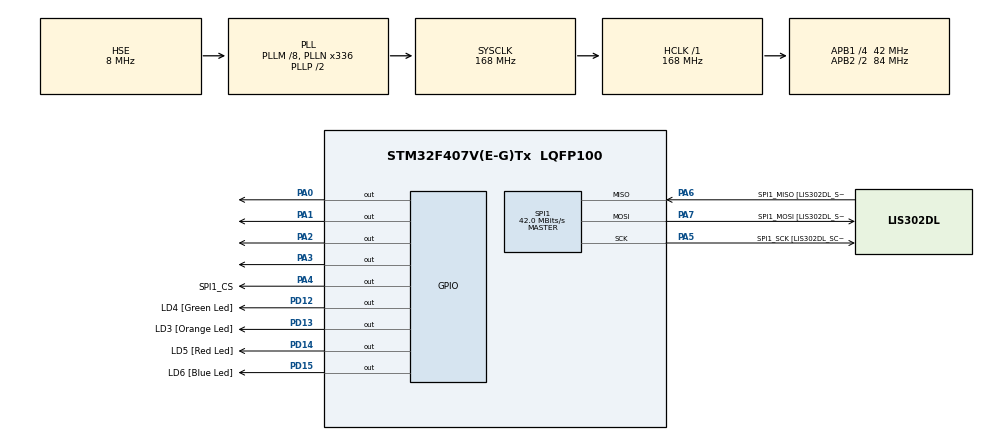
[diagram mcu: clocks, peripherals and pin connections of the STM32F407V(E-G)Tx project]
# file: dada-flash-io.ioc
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Dma.Request0=SPI1_RX
Dma.Request1=SPI1_TX
Dma.SPI1_RX.0.Direction=DMA_PERIPH_TO_MEMORY
Dma.SPI1_RX.0.FIFOMode=DMA_FIFOMODE_DISABLE
Dma.SPI1_RX.0.Instance=DMA2_Stream0
Dma.SPI1_RX.0.MemDataAlignment=DMA_MDATAALIGN_BYTE
Dma.SPI1_RX.0.MemInc=DMA_MINC_ENABLE
Dma.SPI1_RX.0.Mode=DMA_NORMAL
Dma.SPI1_RX.0.PeriphDataAlignment=DMA_PDATAALIGN_BYTE
Dma.SPI1_RX.0.PeriphInc=DMA_PINC_DISABLE
Dma.SPI1_RX.0.Priority=DMA_PRIORITY_LOW
Dma.SPI1_TX.1.Direction=DMA_MEMORY_TO_PERIPH
Dma.SPI1_TX.1.FIFOMode=DMA_FIFOMODE_DISABLE
Dma.SPI1_TX.1.Instance=DMA2_Stream3
Dma.SPI1_TX.1.MemDataAlignment=DMA_MDATAALIGN_BYTE
Dma.SPI1_TX.1.MemInc=DMA_MINC_ENABLE
Dma.SPI1_TX.1.Mode=DMA_NORMAL
Dma.SPI1_TX.1.PeriphDataAlignment=DMA_PDATAALIGN_BYTE
Dma.SPI1_TX.1.PeriphInc=DMA_PINC_DISABLE
Dma.SPI1_TX.1.Priority=DMA_PRIORITY_LOW
Mcu.Family=STM32F4
Mcu.Name=STM32F407V(E-G)Tx
Mcu.Package=LQFP100
NVIC.DMA2_Stream0_IRQn=true\:0\:0\:false\:false\:true\:false\:true
NVIC.DMA2_Stream3_IRQn=true\:0\:0\:false\:false\:true\:false\:true
NVIC.PriorityGroup=NVIC_PRIORITYGROUP_0
NVIC.SPI1_IRQn=true\:0\:0\:false\:false\:true\:true\:true
PA0-WKUP.Signal=GPIO_Output
PA1.Signal=GPIO_Output
PA2.Signal=GPIO_Output
PA3.Signal=GPIO_Output
PA4.GPIO_Label=SPI1_CS
PA4.GPIO_Speed=GPIO_SPEED_FREQ_MEDIUM
PA4.PinState=GPIO_PIN_SET
PA4.Signal=GPIO_Output
PA5.GPIO_Label=SPI1_SCK [LIS302DL_SCL/SPC]
PA5.GPIO_Mode=GPIO_MODE_AF_PP
PA5.GPIO_PuPd=GPIO_NOPULL
PA5.GPIO_Speed=GPIO_SPEED_FREQ_HIGH
PA5.Mode=Full_Duplex_Master
PA5.Signal=SPI1_SCK
PA6.GPIO_Label=SPI1_MISO [LIS302DL_SDO]
PA6.GPIO_Mode=GPIO_MODE_AF_PP
PA6.GPIO_PuPd=GPIO_NOPULL
PA6.GPIO_Speed=GPIO_SPEED_FREQ_HIGH
PA6.Mode=Full_Duplex_Master
PA6.Signal=SPI1_MISO
PA7.GPIO_Label=SPI1_MOSI [LIS302DL_SDA/SDI/SDO]
PA7.GPIO_Mode=GPIO_MODE_AF_PP
PA7.GPIO_PuPd=GPIO_NOPULL
PA7.GPIO_Speed=GPIO_SPEED_FREQ_HIGH
PA7.Mode=Full_Duplex_Master
PA7.Signal=SPI1_MOSI
PC14-OSC32_IN.GPIO_Label=PC14-OSC32_IN
PC14-OSC32_IN.Mode=LSE-External-Oscillator
PC14-OSC32_IN.Signal=RCC_OSC32_IN
PC15-OSC32_OUT.GPIO_Label=PC15-OSC32_OUT
PC15-OSC32_OUT.Mode=LSE-External-Oscillator
PC15-OSC32_OUT.Signal=RCC_OSC32_OUT
PD12.GPIO_Label=LD4 [Green Led]
PD12.GPIO_PuPd=GPIO_NOPULL
PD12.GPIO_Speed=GPIO_SPEED_FREQ_LOW
PD12.Signal=GPIO_Output
PD13.GPIO_Label=LD3 [Orange Led]
PD13.GPIO_PuPd=GPIO_NOPULL
PD13.GPIO_Speed=GPIO_SPEED_FREQ_LOW
PD13.Signal=GPIO_Output
PD14.GPIO_Label=LD5 [Red Led]
PD14.GPIO_PuPd=GPIO_NOPULL
PD14.GPIO_Speed=GPIO_SPEED_FREQ_LOW
PD14.Signal=GPIO_Output
PD15.GPIO_Label=LD6 [Blue Led]
PD15.GPIO_PuPd=GPIO_NOPULL
PD15.GPIO_Speed=GPIO_SPEED_FREQ_LOW
PD15.Signal=GPIO_Output
PH0-OSC_IN.GPIO_Label=PH0-OSC_IN
PH0-OSC_IN.Mode=HSE-External-Oscillator
PH0-OSC_IN.Signal=RCC_OSC_IN
PH1-OSC_OUT.GPIO_Label=PH1-OSC_OUT
PH1-OSC_OUT.Mode=HSE-External-Oscillator
PH1-OSC_OUT.Signal=RCC_OSC_OUT
ProjectManager.HeapSize=0x200
ProjectManager.StackSize=0x400
ProjectManager.TargetToolchain=STM32CubeIDE
RCC.48MHZClocksFreq_Value=48000000
RCC.AHBFreq_Value=168000000
RCC.APB1CLKDivider=RCC_HCLK_DIV4
RCC.APB1Freq_Value=42000000
RCC.APB1TimFreq_Value=84000000
RCC.APB2CLKDivider=RCC_HCLK_DIV2
RCC.APB2Freq_Value=84000000
RCC.APB2TimFreq_Value=168000000
RCC.CortexFreq_Value=168000000
RCC.HCLKFreq_Value=168000000
RCC.HSE_VALUE=8000000
RCC.HSI_VALUE=16000000
RCC.PLLM=8
RCC.PLLN=336
RCC.PLLQ=7
RCC.PLLSourceVirtual=RCC_PLLSOURCE_HSE
RCC.SYSCLKFreq_VALUE=168000000
RCC.SYSCLKSource=RCC_SYSCLKSOURCE_PLLCLK
RCC.VCOOutputFreq_Value=336000000
SPI1.BaudRatePrescaler=SPI_BAUDRATEPRESCALER_2
SPI1.CLKPhase=SPI_PHASE_1EDGE
SPI1.CLKPolarity=SPI_POLARITY_LOW
SPI1.CalculateBaudRate=42.0 MBits/s
SPI1.DataSize=SPI_DATASIZE_8BIT
SPI1.Direction=SPI_DIRECTION_2LINES
SPI1.FirstBit=SPI_FIRSTBIT_MSB
SPI1.Mode=SPI_MODE_MASTER
SPI1.VirtualType=VM_MASTER
board=STM32F407G-DISC1

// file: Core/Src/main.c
/* USER CODE BEGIN Header */
/**
  ******************************************************************************
  * @file           : main.c
  * @brief          : Main program body
  ******************************************************************************
  * @attention
  *
  * <h2><center>&copy; Copyright (c) 2020 STMicroelectronics.
  * All rights reserved.</center></h2>
  *
  * This software component is licensed by ST under Ultimate Liberty license
  * SLA0044, the "License"; You may not use this file except in compliance with
  * the License. You may obtain a copy of the License at:
  *                             www.st.com/SLA0044
  *
  ******************************************************************************
  */
/* USER CODE END Header */

#include "main.h"

/* USER CODE BEGIN Includes */
#include "w25q.h"

/* USER CODE END Includes */

SPI_HandleTypeDef hspi1;
DMA_HandleTypeDef hdma_spi1_rx;
DMA_HandleTypeDef hdma_spi1_tx;

void SystemClock_Config(void);
static void MX_GPIO_Init(void);
static void MX_DMA_Init(void);
static void MX_SPI1_Init(void);

int main(void)
{

  /* MCU Configuration--------------------------------------------------------*/

  /* Reset of all peripherals, Initializes the Flash interface and the Systick. */
  HAL_Init();

  /* Configure the system clock */
  SystemClock_Config();

  /* Initialize all configured peripherals */
  MX_GPIO_Init();
  MX_DMA_Init();
  MX_SPI1_Init();
  /* USER CODE BEGIN 2 */

  flash_schedule_t flash_data;
  flash_schedule_init(&flash_data);
  /* USER CODE END 2 */

  /* Infinite loop */
  /* USER CODE BEGIN WHILE */
  while (1)
  {
    int idle = flash_schedule_next(&flash_data);

    /* USER CODE END WHILE */

  }
}

void SystemClock_Config(void)
{
  RCC_OscInitTypeDef RCC_OscInitStruct = {0};
  RCC_ClkInitTypeDef RCC_ClkInitStruct = {0};

  /** Configure the main internal regulator output voltage
  */
  __HAL_RCC_PWR_CLK_ENABLE();
  __HAL_PWR_VOLTAGESCALING_CONFIG(PWR_REGULATOR_VOLTAGE_SCALE1);
  /** Initializes the CPU, AHB and APB busses clocks
  */
  RCC_OscInitStruct.OscillatorType = RCC_OSCILLATORTYPE_HSE;
  RCC_OscInitStruct.HSEState = RCC_HSE_ON;
  RCC_OscInitStruct.PLL.PLLState = RCC_PLL_ON;
  RCC_OscInitStruct.PLL.PLLSource = RCC_PLLSOURCE_HSE;
  RCC_OscInitStruct.PLL.PLLM = 8;
  RCC_OscInitStruct.PLL.PLLN = 336;
  RCC_OscInitStruct.PLL.PLLP = RCC_PLLP_DIV2;
  RCC_OscInitStruct.PLL.PLLQ = 7;
  if (HAL_RCC_OscConfig(&RCC_OscInitStruct) != HAL_OK)
  {
    Error_Handler();
  }
  /** Initializes the CPU, AHB and APB busses clocks
  */
  RCC_ClkInitStruct.ClockType = RCC_CLOCKTYPE_HCLK|RCC_CLOCKTYPE_SYSCLK
                              |RCC_CLOCKTYPE_PCLK1|RCC_CLOCKTYPE_PCLK2;
  RCC_ClkInitStruct.SYSCLKSource = RCC_SYSCLKSOURCE_PLLCLK;
  RCC_ClkInitStruct.AHBCLKDivider = RCC_SYSCLK_DIV1;
  RCC_ClkInitStruct.APB1CLKDivider = RCC_HCLK_DIV4;
  RCC_ClkInitStruct.APB2CLKDivider = RCC_HCLK_DIV2;

  if (HAL_RCC_ClockConfig(&RCC_ClkInitStruct, FLASH_LATENCY_5) != HAL_OK)
  {
    Error_Handler();
  }
}

static void MX_SPI1_Init(void)
{

  /* SPI1 parameter configuration*/
  hspi1.Instance = SPI1;
  hspi1.Init.Mode = SPI_MODE_MASTER;
  hspi1.Init.Direction = SPI_DIRECTION_2LINES;
  hspi1.Init.DataSize = SPI_DATASIZE_8BIT;
  hspi1.Init.CLKPolarity = SPI_POLARITY_LOW;
  hspi1.Init.CLKPhase = SPI_PHASE_1EDGE;
  hspi1.Init.NSS = SPI_NSS_SOFT;
  hspi1.Init.BaudRatePrescaler = SPI_BAUDRATEPRESCALER_2;
  hspi1.Init.FirstBit = SPI_FIRSTBIT_MSB;
  hspi1.Init.TIMode = SPI_TIMODE_DISABLE;
  hspi1.Init.CRCCalculation = SPI_CRCCALCULATION_DISABLE;
  hspi1.Init.CRCPolynomial = 10;
  if (HAL_SPI_Init(&hspi1) != HAL_OK)
  {
    Error_Handler();
  }

}

static void MX_DMA_Init(void)
{

  /* DMA controller clock enable */
  __HAL_RCC_DMA2_CLK_ENABLE();

  /* DMA interrupt init */
  /* DMA2_Stream0_IRQn interrupt configuration */
  HAL_NVIC_SetPriority(DMA2_Stream0_IRQn, 0, 0);
  HAL_NVIC_EnableIRQ(DMA2_Stream0_IRQn);
  /* DMA2_Stream3_IRQn interrupt configuration */
  HAL_NVIC_SetPriority(DMA2_Stream3_IRQn, 0, 0);
  HAL_NVIC_EnableIRQ(DMA2_Stream3_IRQn);

}

static void MX_GPIO_Init(void)
{
  GPIO_InitTypeDef GPIO_InitStruct = {0};

  /* GPIO Ports Clock Enable */
  __HAL_RCC_GPIOC_CLK_ENABLE();
  __HAL_RCC_GPIOH_CLK_ENABLE();
  __HAL_RCC_GPIOA_CLK_ENABLE();
  __HAL_RCC_GPIOD_CLK_ENABLE();

  /*Configure GPIO pin Output Level */
  HAL_GPIO_WritePin(GPIOA, GPIO_PIN_0|GPIO_PIN_1|GPIO_PIN_2|GPIO_PIN_3, GPIO_PIN_RESET);

  /*Configure GPIO pin Output Level */
  HAL_GPIO_WritePin(SPI1_CS_GPIO_Port, SPI1_CS_Pin, GPIO_PIN_SET);

  /*Configure GPIO pin Output Level */
  HAL_GPIO_WritePin(GPIOD, LD4_Pin|LD3_Pin|LD5_Pin|LD6_Pin, GPIO_PIN_RESET);

  /*Configure GPIO pins : PA0 PA1 PA2 PA3 */
  GPIO_InitStruct.Pin = GPIO_PIN_0|GPIO_PIN_1|GPIO_PIN_2|GPIO_PIN_3;
  GPIO_InitStruct.Mode = GPIO_MODE_OUTPUT_PP;
  GPIO_InitStruct.Pull = GPIO_NOPULL;
  GPIO_InitStruct.Speed = GPIO_SPEED_FREQ_LOW;
  HAL_GPIO_Init(GPIOA, &GPIO_InitStruct);

  /*Configure GPIO pin : SPI1_CS_Pin */
  GPIO_InitStruct.Pin = SPI1_CS_Pin;
  GPIO_InitStruct.Mode = GPIO_MODE_OUTPUT_PP;
  GPIO_InitStruct.Pull = GPIO_NOPULL;
  GPIO_InitStruct.Speed = GPIO_SPEED_FREQ_MEDIUM;
  HAL_GPIO_Init(SPI1_CS_GPIO_Port, &GPIO_InitStruct);

  /*Configure GPIO pins : LD4_Pin LD3_Pin LD5_Pin LD6_Pin */
  GPIO_InitStruct.Pin = LD4_Pin|LD3_Pin|LD5_Pin|LD6_Pin;
  GPIO_InitStruct.Mode = GPIO_MODE_OUTPUT_PP;
  GPIO_InitStruct.Pull = GPIO_NOPULL;
  GPIO_InitStruct.Speed = GPIO_SPEED_FREQ_LOW;
  HAL_GPIO_Init(GPIOD, &GPIO_InitStruct);

}

void Error_Handler(void)
{
}

/************************ (C) COPYRIGHT STMicroelectronics *****END OF FILE****/
